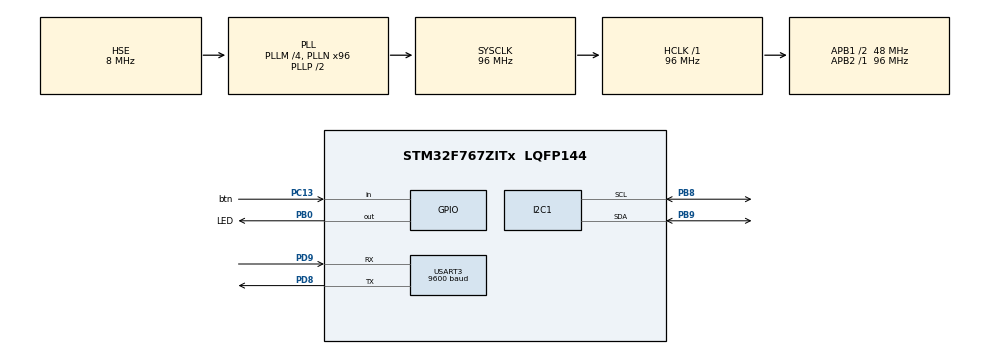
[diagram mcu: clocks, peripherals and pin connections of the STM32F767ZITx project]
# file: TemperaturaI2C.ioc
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I2C1.I2C_Fall_Time=100
I2C1.I2C_Rise_Time=100
I2C1.Timing=0x10805D88
Mcu.Family=STM32F7
Mcu.Name=STM32F767ZITx
Mcu.Package=LQFP144
NVIC.PriorityGroup=NVIC_PRIORITYGROUP_4
PB0.GPIO_Label=LED
PB0.Signal=GPIO_Output
PB8.Mode=I2C
PB8.Signal=I2C1_SCL
PB9.Mode=I2C
PB9.Signal=I2C1_SDA
PC13.GPIO_Label=btn
PC13.GPIO_PuPd=GPIO_PULLDOWN
PC13.Signal=GPIO_Input
PD8.Mode=Asynchronous
PD8.Signal=USART3_TX
PD9.Mode=Asynchronous
PD9.Signal=USART3_RX
PH0/OSC_IN.Mode=HSE-External-Oscillator
PH0/OSC_IN.Signal=RCC_OSC_IN
PH1/OSC_OUT.Mode=HSE-External-Oscillator
PH1/OSC_OUT.Signal=RCC_OSC_OUT
ProjectManager.HeapSize=0x200
ProjectManager.StackSize=0x400
ProjectManager.TargetToolchain=STM32CubeIDE
RCC.48MHZClocksFreq_Value=24000000
RCC.AHBFreq_Value=96000000
RCC.APB1CLKDivider=RCC_HCLK_DIV2
RCC.APB1Freq_Value=48000000
RCC.APB1TimFreq_Value=96000000
RCC.APB2Freq_Value=96000000
RCC.APB2TimFreq_Value=96000000
RCC.CortexFreq_Value=96000000
RCC.HCLKFreq_Value=96000000
RCC.HSE_VALUE=8000000
RCC.HSI_VALUE=16000000
RCC.LSE_VALUE=32768
RCC.PLLM=4
RCC.PLLMUL=RCC_PLL_MUL9
RCC.PLLN=96
RCC.PLLQ=4
RCC.PLLSourceVirtual=RCC_PLLSOURCE_HSE
RCC.PRESCALERUSB=RCC_USBCLKSOURCE_PLL_DIV1_5
RCC.SYSCLKFreq_VALUE=96000000
RCC.SYSCLKSource=RCC_SYSCLKSOURCE_PLLCLK
RCC.SYSCLKSourceVirtual=RCC_SYSCLKSOURCE_PLLCLK
RCC.USBFreq_Value=48000000
RCC.VCOOutputFreq_Value=192000000
TIM2.Period=5000-1
TIM2.Prescaler=32000-1
USART3.BaudRate=9600
USART3.VirtualMode-Asynchronous=VM_ASYNC
VP_TIM2_VS_ClockSourceINT.Mode=Internal
board=NUCLEO-F767ZI

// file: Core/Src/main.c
/* USER CODE BEGIN Header */
/**
 ******************************************************************************
 * @file           : main.c
 * @brief          : Main program body
 ******************************************************************************
 * @attention
 *
 * Copyright (c) 2022 STMicroelectronics.
 * All rights reserved.
 *
 * This software is licensed under terms that can be found in the LICENSE file
 * in the root directory of this software component.
 * If no LICENSE file comes with this software, it is provided AS-IS.
 *
 *
 ******************************************************************************
 ******************************************************************************
 *Autores: Jhan Carlos Reyes
 *Autores: Jose Luis De La Hoz
 *Autores: Esneider Silva
 *
 * El siguiente código presenta un desarrollo en la tarjeta de desarrollo
 * Nucleo - F767zi con un ARM-Cortex M7
 *
 * Consiste en una interfaz de terminar serial por la cual el usuario puede
 * interactuar de manera amigable para la generación de número pseudoaleatorios
 * mediante el uso de desplazamientos y compuertas XOR con determinadas
 * posiciones o taps
 *
 * Dentro de las características del programa está la interfaz antes mencionada
 * que transmite a 9600 bps 8N1. Además de identificar si se optienen periodo
 * máximo durante la generación. Si utiliza una única salida que corresponde al
 * led verde en la tarjeta
 ******************************************************************************
 ******************************************************************************
 */
/* USER CODE END Header */
#include "main.h"

/* USER CODE BEGIN Includes */

//Adición de librerías para
// transmisión UART stdio y string
#include <stdio.h>
#include <stdlib.h>
#include <string.h>
// cálculos matemáticos (potencia)
#include <math.h>
// incluir las funciones de printf y scanf
#include "retarget.h"
#include "funciones.h"

/* USER CODE END Includes */

I2C_HandleTypeDef hi2c1;

TIM_HandleTypeDef htim2;

UART_HandleTypeDef huart3;

void SystemClock_Config(void);
static void MX_GPIO_Init(void);
static void MX_USART3_UART_Init(void);
static void MX_TIM2_Init(void);
static void MX_I2C1_Init(void);

int main(void)
{

  /* MCU Configuration--------------------------------------------------------*/

  /* Reset of all peripherals, Initializes the Flash interface and the Systick. */
  HAL_Init();

  /* Configure the system clock */
  SystemClock_Config();

  /* Initialize all configured peripherals */
  MX_GPIO_Init();
  MX_USART3_UART_Init();
  MX_TIM2_Init();
  MX_I2C1_Init();
  /* USER CODE BEGIN 2 */
  RetargetInit(&huart3); // declarar Uart3 (conectado con el stlink)
  uint8_t bufe[] = "error\r\n";
   char buffer[12];
   uint8_t buff_rx[2] = {0};
   uint8_t buff_tx[2] = {0};
   static const uint8_t ADDR_W = 0x90;
   static const uint8_t POINTER_Temp = 0x00;
   uint16_t val = 0;
   uint16_t a1 = 0;
   uint16_t a0 = 0;
   float temp;
   HAL_StatusTypeDef ret;

   buff_tx[0]= POINTER_Temp;

	uint8_t buff[4]={0};	//Transmitir

	Saludo();

	while (1){
		ret = HAL_I2C_Master_Transmit(&hi2c1, ADDR_W, buff_tx, 1, HAL_MAX_DELAY);

			  if (ret == HAL_OK){

				  ret = HAL_I2C_Master_Receive(&hi2c1, ADDR_W, buff_rx, 2, HAL_MAX_DELAY);

				  if(ret == HAL_OK){

					  a1 = buff_rx[1];
					  a1 = (a1 >> 5);

					  a0 = buff_rx[0];
					  a0 = (a0 << 3);

					  val = (a0 | a1);

					  temp = val*0.125;

					 // gcvt(temp, 3, buffer);

					  //HAL_UART_Transmit(&huart3, (uint8_t*)buffer, sizeof(buffer), HAL_MAX_DELAY);
					 // HAL_Delay(400);
					  itoa(val, (char*) buff, 10);
					  //gcvt(temp, 4, buff);

					  printf("%.6f\r\n", temp);
					  HAL_Delay(500);
				  }
			  }

			  if (ret != HAL_OK){
				  HAL_UART_Transmit(&huart3, bufe, sizeof(bufe), HAL_MAX_DELAY);
				  HAL_Delay(300);
			  }
	}

    /* USER CODE END WHILE */

}

void SystemClock_Config(void)
{
  RCC_OscInitTypeDef RCC_OscInitStruct = {0};
  RCC_ClkInitTypeDef RCC_ClkInitStruct = {0};

  /** Configure the main internal regulator output voltage
  */
  __HAL_RCC_PWR_CLK_ENABLE();
  __HAL_PWR_VOLTAGESCALING_CONFIG(PWR_REGULATOR_VOLTAGE_SCALE3);

  /** Initializes the RCC Oscillators according to the specified parameters
  * in the RCC_OscInitTypeDef structure.
  */
  RCC_OscInitStruct.OscillatorType = RCC_OSCILLATORTYPE_HSE;
  RCC_OscInitStruct.HSEState = RCC_HSE_ON;
  RCC_OscInitStruct.PLL.PLLState = RCC_PLL_ON;
  RCC_OscInitStruct.PLL.PLLSource = RCC_PLLSOURCE_HSE;
  RCC_OscInitStruct.PLL.PLLM = 4;
  RCC_OscInitStruct.PLL.PLLN = 96;
  RCC_OscInitStruct.PLL.PLLP = RCC_PLLP_DIV2;
  RCC_OscInitStruct.PLL.PLLQ = 4;
  RCC_OscInitStruct.PLL.PLLR = 2;
  if (HAL_RCC_OscConfig(&RCC_OscInitStruct) != HAL_OK)
  {
    Error_Handler();
  }

  /** Activate the Over-Drive mode
  */
  if (HAL_PWREx_EnableOverDrive() != HAL_OK)
  {
    Error_Handler();
  }

  /** Initializes the CPU, AHB and APB buses clocks
  */
  RCC_ClkInitStruct.ClockType = RCC_CLOCKTYPE_HCLK|RCC_CLOCKTYPE_SYSCLK
                              |RCC_CLOCKTYPE_PCLK1|RCC_CLOCKTYPE_PCLK2;
  RCC_ClkInitStruct.SYSCLKSource = RCC_SYSCLKSOURCE_PLLCLK;
  RCC_ClkInitStruct.AHBCLKDivider = RCC_SYSCLK_DIV1;
  RCC_ClkInitStruct.APB1CLKDivider = RCC_HCLK_DIV2;
  RCC_ClkInitStruct.APB2CLKDivider = RCC_HCLK_DIV1;

  if (HAL_RCC_ClockConfig(&RCC_ClkInitStruct, FLASH_LATENCY_3) != HAL_OK)
  {
    Error_Handler();
  }
}

static void MX_I2C1_Init(void)
{

  hi2c1.Instance = I2C1;
  hi2c1.Init.Timing = 0x10805D88;
  hi2c1.Init.OwnAddress1 = 0;
  hi2c1.Init.AddressingMode = I2C_ADDRESSINGMODE_7BIT;
  hi2c1.Init.DualAddressMode = I2C_DUALADDRESS_DISABLE;
  hi2c1.Init.OwnAddress2 = 0;
  hi2c1.Init.OwnAddress2Masks = I2C_OA2_NOMASK;
  hi2c1.Init.GeneralCallMode = I2C_GENERALCALL_DISABLE;
  hi2c1.Init.NoStretchMode = I2C_NOSTRETCH_DISABLE;
  if (HAL_I2C_Init(&hi2c1) != HAL_OK)
  {
    Error_Handler();
  }

  /** Configure Analogue filter
  */
  if (HAL_I2CEx_ConfigAnalogFilter(&hi2c1, I2C_ANALOGFILTER_ENABLE) != HAL_OK)
  {
    Error_Handler();
  }

  /** Configure Digital filter
  */
  if (HAL_I2CEx_ConfigDigitalFilter(&hi2c1, 0) != HAL_OK)
  {
    Error_Handler();
  }

}

static void MX_TIM2_Init(void)
{

  TIM_ClockConfigTypeDef sClockSourceConfig = {0};
  TIM_MasterConfigTypeDef sMasterConfig = {0};

  htim2.Instance = TIM2;
  htim2.Init.Prescaler = 32000-1;
  htim2.Init.CounterMode = TIM_COUNTERMODE_UP;
  htim2.Init.Period = 5000-1;
  htim2.Init.ClockDivision = TIM_CLOCKDIVISION_DIV1;
  htim2.Init.AutoReloadPreload = TIM_AUTORELOAD_PRELOAD_DISABLE;
  if (HAL_TIM_Base_Init(&htim2) != HAL_OK)
  {
    Error_Handler();
  }
  sClockSourceConfig.ClockSource = TIM_CLOCKSOURCE_INTERNAL;
  if (HAL_TIM_ConfigClockSource(&htim2, &sClockSourceConfig) != HAL_OK)
  {
    Error_Handler();
  }
  sMasterConfig.MasterOutputTrigger = TIM_TRGO_RESET;
  sMasterConfig.MasterSlaveMode = TIM_MASTERSLAVEMODE_DISABLE;
  if (HAL_TIMEx_MasterConfigSynchronization(&htim2, &sMasterConfig) != HAL_OK)
  {
    Error_Handler();
  }

}

static void MX_USART3_UART_Init(void)
{

  huart3.Instance = USART3;
  huart3.Init.BaudRate = 9600;
  huart3.Init.WordLength = UART_WORDLENGTH_8B;
  huart3.Init.StopBits = UART_STOPBITS_1;
  huart3.Init.Parity = UART_PARITY_NONE;
  huart3.Init.Mode = UART_MODE_TX_RX;
  huart3.Init.HwFlowCtl = UART_HWCONTROL_NONE;
  huart3.Init.OverSampling = UART_OVERSAMPLING_16;
  huart3.Init.OneBitSampling = UART_ONE_BIT_SAMPLE_DISABLE;
  huart3.AdvancedInit.AdvFeatureInit = UART_ADVFEATURE_NO_INIT;
  if (HAL_UART_Init(&huart3) != HAL_OK)
  {
    Error_Handler();
  }

}

static void MX_GPIO_Init(void)
{
  GPIO_InitTypeDef GPIO_InitStruct = {0};

  /* GPIO Ports Clock Enable */
  __HAL_RCC_GPIOC_CLK_ENABLE();
  __HAL_RCC_GPIOH_CLK_ENABLE();
  __HAL_RCC_GPIOB_CLK_ENABLE();
  __HAL_RCC_GPIOD_CLK_ENABLE();

  /*Configure GPIO pin Output Level */
  HAL_GPIO_WritePin(LED_GPIO_Port, LED_Pin, GPIO_PIN_RESET);

  /*Configure GPIO pin : btn_Pin */
  GPIO_InitStruct.Pin = btn_Pin;
  GPIO_InitStruct.Mode = GPIO_MODE_INPUT;
  GPIO_InitStruct.Pull = GPIO_PULLDOWN;
  HAL_GPIO_Init(btn_GPIO_Port, &GPIO_InitStruct);

  /*Configure GPIO pin : LED_Pin */
  GPIO_InitStruct.Pin = LED_Pin;
  GPIO_InitStruct.Mode = GPIO_MODE_OUTPUT_PP;
  GPIO_InitStruct.Pull = GPIO_NOPULL;
  GPIO_InitStruct.Speed = GPIO_SPEED_FREQ_LOW;
  HAL_GPIO_Init(LED_GPIO_Port, &GPIO_InitStruct);

}

void Error_Handler(void)
{
	__disable_irq();
	while (1) {
	}
}
